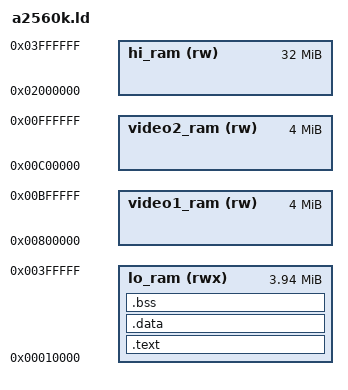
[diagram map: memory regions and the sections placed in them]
STARTUP(mcp-crt0.o)
OUTPUT_ARCH(m68k)
OUTPUT_FORMAT(elf32-m68k)
SEARCH_DIR(.)
GROUP(-la2560k -lc -lgcc)
__DYNAMIC  =  0;

MEMORY
{
  lo_ram      (rwx) : ORIGIN = 0x00010000, LENGTH = 4M - 64K
  video1_ram  (rw)  : ORIGIN = 0x00800000, LENGTH = 4M
  video2_ram  (rw)  : ORIGIN = 0x00C00000, LENGTH = 4M
  hi_ram      (rw)  : ORIGIN = 0x02000000, LENGTH = 32M
}

/*
 * allocate the stack to be at the top of memory, since the stack
 * grows down
 */

/*
 * If __stack set to 0, the OS supplied stack is used (0x1000 on MCP)
 */
PROVIDE (__stack = 0);

/*
 * Initalize some symbols to be zero so we can reference them in the
 * crt0 without core dumping. These functions are all optional, but
 * we do this so we can have our crt0 always use them if they exist. 
 * This is so BSPs work better when using the crt0 installed with gcc.
 * We have to initalize them twice, so we cover a.out (which prepends
 * an underscore) and coff object file formats.
 */
PROVIDE (hardware_init_hook = 0);
PROVIDE (_hardware_init_hook = 0);
PROVIDE (software_init_hook = 0);
PROVIDE (_software_init_hook = 0);
/*
 * stick everything in ram (of course)
 */
SECTIONS
{
  .text :
  {
    CREATE_OBJECT_SYMBOLS
    *(.text .text.*)

    . = ALIGN(0x4);
    /* These are for running static constructors and destructors under ELF.  */
    KEEP (*crtbegin.o(.ctors))
    KEEP (*(EXCLUDE_FILE (*crtend.o) .ctors))
    KEEP (*(SORT(.ctors.*)))
    KEEP (*(.ctors))
    KEEP (*crtbegin.o(.dtors))
    KEEP (*(EXCLUDE_FILE (*crtend.o) .dtors))
    KEEP (*(SORT(.dtors.*)))
    KEEP (*(.dtors))

    *(.rodata .rodata.*)

    . = ALIGN(0x4);
    *(.gcc_except_table) 

    . = ALIGN(0x4);
    *(.eh_frame)

    . = ALIGN(0x4);
    __INIT_SECTION__ = . ;
    LONG (0x4e560000)	/* linkw %fp,#0 */
    *(.init)
    SHORT (0x4e5e)	/* unlk %fp */
    SHORT (0x4e75)	/* rts */

    . = ALIGN(0x4);
    __FINI_SECTION__ = . ;
    LONG (0x4e560000)	/* linkw %fp,#0 */
    *(.fini)
    SHORT (0x4e5e)	/* unlk %fp */
    SHORT (0x4e75)	/* rts */

    _etext = .;
    *(.lit)
  } > lo_ram

  .data :
  {
    *(.got.plt) *(.got)
    *(.shdata)
    *(.data .data.*)
    _edata = .;
  } > lo_ram

  .bss :
  {
    . = ALIGN(0x4);
    __bss_start = . ;
    *(.shbss)
    *(.bss .bss.*)
    *(COMMON)
    _end =  ALIGN (0x8);
    __end = _end;
  } > lo_ram

  .stab 0 (NOLOAD) :
  {
    *(.stab)
  }

  .stabstr 0 (NOLOAD) :
  {
    *(.stabstr)
  }
}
